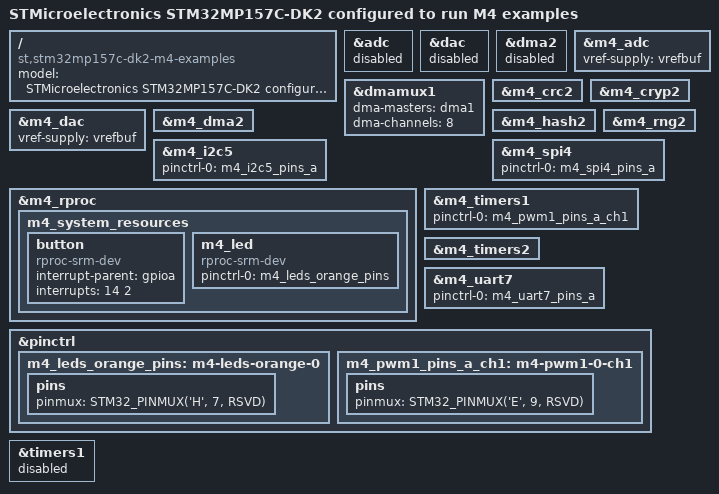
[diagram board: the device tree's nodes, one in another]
// SPDX-License-Identifier: (GPL-2.0+ OR BSD-3-Clause)
/*
 * Copyright (C) STMicroelectronics 2017 - All Rights Reserved
 * Author: Alexandre Torgue <alexandre.torgue@st.com> for STMicroelectronics.
 */

/dts-v1/;

#include "stm32mp157c-dk2.dts"

/ {
	model = "STMicroelectronics STM32MP157C-DK2 configured to run M4 examples";
	compatible = "st,stm32mp157c-dk2-m4-examples", "st,stm32mp157c-dk2", "st,stm32mp157";
};

&adc {
	status = "disabled";
};

&dac {
	status = "disabled";
};

&dma2 {
	status = "disabled";
};

&dmamux1 {
	dma-masters = <&dma1>;
	dma-channels = <8>;
};

&m4_adc {
	vref-supply = <&vrefbuf>;
	status = "okay";
};

&m4_crc2 {
	status = "okay";
};

&m4_cryp2 {
	status = "okay";
};

&m4_dac {
	vref-supply = <&vrefbuf>;
	status = "okay";
};

&m4_dma2 {
	status = "okay";
};

&m4_hash2 {
	status = "okay";
};

&m4_i2c5 {
	pinctrl-names = "default";
	pinctrl-0 = <&m4_i2c5_pins_a>;
	status = "okay";
};

&m4_rng2 {
	status = "okay";
};

&m4_rproc {
	m4_system_resources {
		status = "okay";

		button {
			compatible = "rproc-srm-dev";
			interrupt-parent = <&gpioa>;
			interrupts = <14 2>;
			interrupt-names = "irq";
			status = "okay";
		};

		m4_led: m4_led {
			compatible = "rproc-srm-dev";
			pinctrl-names = "default";
			pinctrl-0 = <&m4_leds_orange_pins>;
			status = "okay";
		};
	};
};

&m4_spi4 {
	pinctrl-names = "default";
	pinctrl-0 = <&m4_spi4_pins_a>;
	status = "okay";
};

&m4_timers1 {
	pinctrl-names = "default";
	pinctrl-0 = <&m4_pwm1_pins_a_ch1>;
	status = "okay";
};

&m4_timers2 {
	status = "okay";
};

&m4_uart7 {
	pinctrl-names = "default";
	pinctrl-0 = <&m4_uart7_pins_a>;
	status = "okay";
};

&pinctrl {
	m4_leds_orange_pins: m4-leds-orange-0 {
		pins {
			pinmux = <STM32_PINMUX('H', 7, RSVD)>;
		};
	};

	m4_pwm1_pins_a_ch1: m4-pwm1-0-ch1 {
		pins {
			pinmux = <STM32_PINMUX('E', 9, RSVD)>;
		};
	};
};

&timers1 {
	status = "disabled";
};
